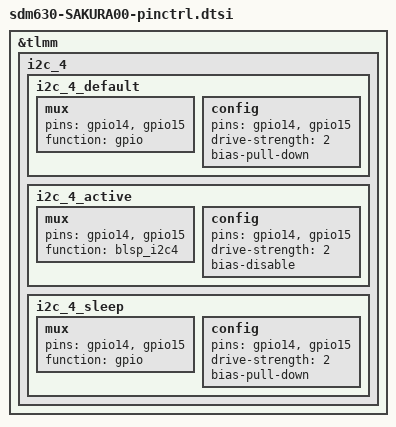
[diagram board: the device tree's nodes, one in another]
/*
 * This software is contributed or developed by KYOCERA Corporation.
 * (C) 2018 KYOCERA Corporation
 *
 * This program is free software; you can redistribute it and/or modify
 * it under the terms of the GNU General Public License version 2 and
 * only version 2 as published by the Free Software Foundation.
 *
 * This program is distributed in the hope that it will be useful,
 * but WITHOUT ANY WARRANTY; without even the implied warranty of
 * MERCHANTABILITY or FITNESS FOR A PARTICULAR PURPOSE.  See the
 * GNU General Public License for more details.
 */

&tlmm {

	i2c_4 {
		i2c_4_default: i2c_4_default {
			mux {
				pins = "gpio14", "gpio15";
				function = "gpio";
			};

			config {
				pins = "gpio14", "gpio15";
				drive-strength = <2>;
				bias-pull-down;
			};
		};

		i2c_4_active: i2c_4_active {
			mux {
				pins = "gpio14", "gpio15";
				function = "blsp_i2c4";
			};

			config {
				pins = "gpio14", "gpio15";
				drive-strength = <2>;
				bias-disable;
			};
		};

		i2c_4_sleep: i2c_4_sleep {
			mux {
				pins = "gpio14", "gpio15";
				function = "gpio";
			};

			config {
				pins = "gpio14", "gpio15";
				drive-strength = <2>;
				bias-pull-down;
			};
		};
	};
};
